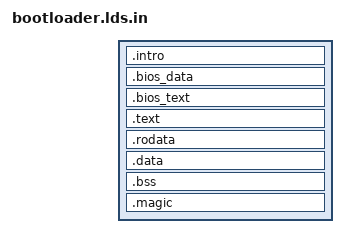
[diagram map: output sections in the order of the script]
OUTPUT_FORMAT(elf64-x86-64)

SECTIONS
{
    . = @F_BOOTLOADER_MEMORY_LOCATION@;

    .intro :
    {
        KEEP(*(.intro))
    }

    .bios_data :
    {
        *(.bios_data*)
    }

    .bios_text :
    {
        *(.bios_text*)
    }

    .text :
    {
        *(.text*)
    }

    . = ALIGN(0x200);

    .rodata :
    {
        *(.rodata*)
    }

    . = ALIGN(0x200);

    .data :
    {
        *(.data*)
    }

    . = ALIGN(0x200);

    .bss :
    {
        *(.bss*)
    }

    . = ALIGN(0x200 - 4);
    HEAP_START = .;

    .magic :
    {
        LONG(@F_BOOTLOADER_MAGIC@);
    }
}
